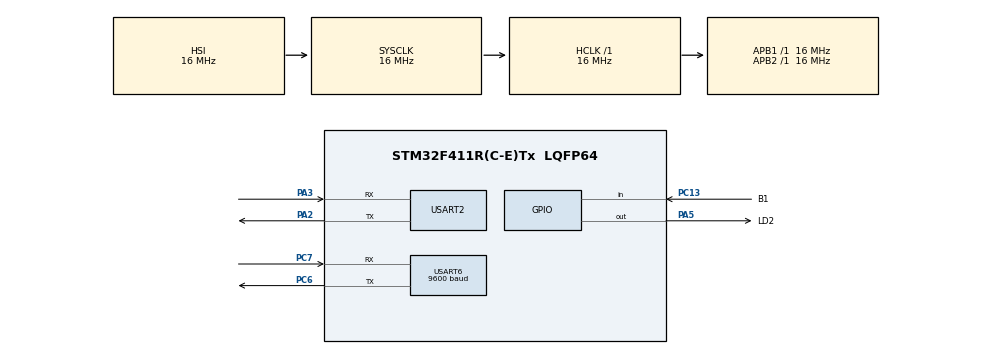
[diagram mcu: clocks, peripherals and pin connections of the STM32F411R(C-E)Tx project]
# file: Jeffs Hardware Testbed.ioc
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Dma.Request0=USART6_TX
Dma.USART6_TX.0.Direction=DMA_MEMORY_TO_PERIPH
Dma.USART6_TX.0.FIFOMode=DMA_FIFOMODE_DISABLE
Dma.USART6_TX.0.Instance=DMA2_Stream6
Dma.USART6_TX.0.MemDataAlignment=DMA_MDATAALIGN_BYTE
Dma.USART6_TX.0.MemInc=DMA_MINC_ENABLE
Dma.USART6_TX.0.Mode=DMA_NORMAL
Dma.USART6_TX.0.PeriphDataAlignment=DMA_PDATAALIGN_BYTE
Dma.USART6_TX.0.PeriphInc=DMA_PINC_DISABLE
Dma.USART6_TX.0.Priority=DMA_PRIORITY_LOW
FREERTOS.INCLUDE_vTaskDelayUntil=1
FREERTOS.Tasks01=myTask01,0,128,StartDefaultTask,Default,NULL,Static,myTask01Buffer,myTask01ControlBlock;myTask02,3,128,StartTask02,Default,NULL,Static,myTask02Buffer,myTask02ControlBlock
FREERTOS.configENABLE_FPU=1
Mcu.Family=STM32F4
Mcu.Name=STM32F411R(C-E)Tx
Mcu.Package=LQFP64
NVIC.DMA2_Stream6_IRQn=true\:5\:0\:false\:false\:true\:true\:false\:true
NVIC.PriorityGroup=NVIC_PRIORITYGROUP_4
NVIC.USART6_IRQn=true\:5\:0\:false\:false\:true\:true\:true\:true
PA2.Mode=Asynchronous
PA2.Signal=USART2_TX
PA3.Mode=Asynchronous
PA3.Signal=USART2_RX
PA5.GPIO_Label=LD2
PA5.Signal=GPIO_Output
PC13-ANTI_TAMP.GPIO_Label=B1
PC13-ANTI_TAMP.Signal=GPIO_Input
PC6.Mode=Asynchronous
PC6.Signal=USART6_TX
PC7.Mode=Asynchronous
PC7.Signal=USART6_RX
ProjectManager.HeapSize=0x200
ProjectManager.StackSize=0x400
ProjectManager.TargetToolchain=STM32CubeIDE
RCC.AHBFreq_Value=16000000
RCC.APB1Freq_Value=16000000
RCC.APB2Freq_Value=16000000
RCC.CortexFreq_Value=16000000
RCC.HSE_VALUE=25000000
RCC.HSI_VALUE=16000000
RCC.LSE_VALUE=32768
RCC.SYSCLKFreq_VALUE=16000000
RCC.VCOOutputFreq_Value=192000000
USART2.VirtualMode=VM_ASYNC
USART6.BaudRate=9600
USART6.VirtualMode=VM_ASYNC
VP_FREERTOS_VS_CMSIS_V1.Mode=CMSIS_V1
board=custom

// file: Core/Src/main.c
/* USER CODE BEGIN Header */
/**
  ******************************************************************************
  * @file           : main.c
  * @brief          : Main program body
  ******************************************************************************
  * @attention
  *
  * <h2><center>&copy; Copyright (c) 2021 STMicroelectronics.
  * All rights reserved.</center></h2>
  *
  * This software component is licensed by ST under Ultimate Liberty license
  * SLA0044, the "License"; You may not use this file except in compliance with
  * the License. You may obtain a copy of the License at:
  *                             www.st.com/SLA0044
  *
  ******************************************************************************
  */
/* USER CODE END Header */
#include "main.h"
#include "cmsis_os.h"

/* USER CODE BEGIN Includes */
#include "Nucleo_Profiles.h"
/* USER CODE END Includes */

UART_HandleTypeDef huart2;
UART_HandleTypeDef huart6;
DMA_HandleTypeDef hdma_usart6_tx;

osThreadId myTask01Handle;
uint32_t myTask01Buffer[ 128 ];
osStaticThreadDef_t myTask01ControlBlock;
osThreadId myTask02Handle;
uint32_t myTask02Buffer[ 128 ];
osStaticThreadDef_t myTask02ControlBlock;

void SystemClock_Config(void);
static void MX_GPIO_Init(void);
static void MX_DMA_Init(void);
static void MX_USART2_UART_Init(void);
static void MX_USART6_UART_Init(void);
void StartDefaultTask(void const * argument);
void StartTask02(void const * argument);

int main(void)
{

  /* MCU Configuration--------------------------------------------------------*/

  /* Reset of all peripherals, Initializes the Flash interface and the Systick. */
  HAL_Init();

  /* Configure the system clock */
  SystemClock_Config();

  /* Initialize all configured peripherals */
  MX_GPIO_Init();
  MX_DMA_Init();
  MX_USART2_UART_Init();
  MX_USART6_UART_Init();
  /* USER CODE BEGIN 2 */
  NucleoF4_Init();
  /* USER CODE END 2 */

  /* Create the thread(s) */
  /* definition and creation of myTask01 */
  osThreadStaticDef(myTask01, StartDefaultTask, osPriorityNormal, 0, 128, myTask01Buffer, &myTask01ControlBlock);
  myTask01Handle = osThreadCreate(osThread(myTask01), NULL);

  /* definition and creation of myTask02 */
  osThreadStaticDef(myTask02, StartTask02, osPriorityRealtime, 0, 128, myTask02Buffer, &myTask02ControlBlock);
  myTask02Handle = osThreadCreate(osThread(myTask02), NULL);

  /* Start scheduler */
  osKernelStart();

  /* We should never get here as control is now taken by the scheduler */
  /* Infinite loop */
  while (1)
  {

  }
}

void SystemClock_Config(void)
{
  RCC_OscInitTypeDef RCC_OscInitStruct = {0};
  RCC_ClkInitTypeDef RCC_ClkInitStruct = {0};

  /** Configure the main internal regulator output voltage
  */
  __HAL_RCC_PWR_CLK_ENABLE();
  __HAL_PWR_VOLTAGESCALING_CONFIG(PWR_REGULATOR_VOLTAGE_SCALE1);
  /** Initializes the RCC Oscillators according to the specified parameters
  * in the RCC_OscInitTypeDef structure.
  */
  RCC_OscInitStruct.OscillatorType = RCC_OSCILLATORTYPE_HSI;
  RCC_OscInitStruct.HSIState = RCC_HSI_ON;
  RCC_OscInitStruct.HSICalibrationValue = RCC_HSICALIBRATION_DEFAULT;
  RCC_OscInitStruct.PLL.PLLState = RCC_PLL_NONE;
  if (HAL_RCC_OscConfig(&RCC_OscInitStruct) != HAL_OK)
  {
    Error_Handler();
  }
  /** Initializes the CPU, AHB and APB buses clocks
  */
  RCC_ClkInitStruct.ClockType = RCC_CLOCKTYPE_HCLK|RCC_CLOCKTYPE_SYSCLK
                              |RCC_CLOCKTYPE_PCLK1|RCC_CLOCKTYPE_PCLK2;
  RCC_ClkInitStruct.SYSCLKSource = RCC_SYSCLKSOURCE_HSI;
  RCC_ClkInitStruct.AHBCLKDivider = RCC_SYSCLK_DIV1;
  RCC_ClkInitStruct.APB1CLKDivider = RCC_HCLK_DIV1;
  RCC_ClkInitStruct.APB2CLKDivider = RCC_HCLK_DIV1;

  if (HAL_RCC_ClockConfig(&RCC_ClkInitStruct, FLASH_LATENCY_0) != HAL_OK)
  {
    Error_Handler();
  }
}

static void MX_USART2_UART_Init(void)
{

  huart2.Instance = USART2;
  huart2.Init.BaudRate = 115200;
  huart2.Init.WordLength = UART_WORDLENGTH_8B;
  huart2.Init.StopBits = UART_STOPBITS_1;
  huart2.Init.Parity = UART_PARITY_NONE;
  huart2.Init.Mode = UART_MODE_TX_RX;
  huart2.Init.HwFlowCtl = UART_HWCONTROL_NONE;
  huart2.Init.OverSampling = UART_OVERSAMPLING_16;
  if (HAL_UART_Init(&huart2) != HAL_OK)
  {
    Error_Handler();
  }

}

static void MX_USART6_UART_Init(void)
{

  huart6.Instance = USART6;
  huart6.Init.BaudRate = 9600;
  huart6.Init.WordLength = UART_WORDLENGTH_8B;
  huart6.Init.StopBits = UART_STOPBITS_1;
  huart6.Init.Parity = UART_PARITY_NONE;
  huart6.Init.Mode = UART_MODE_TX_RX;
  huart6.Init.HwFlowCtl = UART_HWCONTROL_NONE;
  huart6.Init.OverSampling = UART_OVERSAMPLING_16;
  if (HAL_UART_Init(&huart6) != HAL_OK)
  {
    Error_Handler();
  }

}

static void MX_DMA_Init(void)
{

  /* DMA controller clock enable */
  __HAL_RCC_DMA2_CLK_ENABLE();

  /* DMA interrupt init */
  /* DMA2_Stream6_IRQn interrupt configuration */
  HAL_NVIC_SetPriority(DMA2_Stream6_IRQn, 5, 0);
  HAL_NVIC_EnableIRQ(DMA2_Stream6_IRQn);

}

static void MX_GPIO_Init(void)
{
  GPIO_InitTypeDef GPIO_InitStruct = {0};

  /* GPIO Ports Clock Enable */
  __HAL_RCC_GPIOC_CLK_ENABLE();
  __HAL_RCC_GPIOA_CLK_ENABLE();

  /*Configure GPIO pin Output Level */
  HAL_GPIO_WritePin(LD2_GPIO_Port, LD2_Pin, GPIO_PIN_RESET);

  /*Configure GPIO pin : B1_Pin */
  GPIO_InitStruct.Pin = B1_Pin;
  GPIO_InitStruct.Mode = GPIO_MODE_INPUT;
  GPIO_InitStruct.Pull = GPIO_NOPULL;
  HAL_GPIO_Init(B1_GPIO_Port, &GPIO_InitStruct);

  /*Configure GPIO pin : LD2_Pin */
  GPIO_InitStruct.Pin = LD2_Pin;
  GPIO_InitStruct.Mode = GPIO_MODE_OUTPUT_PP;
  GPIO_InitStruct.Pull = GPIO_NOPULL;
  GPIO_InitStruct.Speed = GPIO_SPEED_FREQ_LOW;
  HAL_GPIO_Init(LD2_GPIO_Port, &GPIO_InitStruct);

}

void StartDefaultTask(void const * argument)
{
  /* USER CODE BEGIN 5 */
  static TickType_t time_init = 0;

  /* Infinite loop */
  while(1) {

	  vTaskDelayUntil(&time_init, 100/portTICK_RATE_MS);
  }
  vTaskDelete(NULL);
  /* USER CODE END 5 */
}

void StartTask02(void const * argument)
{
  /* USER CODE BEGIN StartTask02 */
  /* Infinite loop */
  while(1) {
    break;
  }
  vTaskDelete(NULL);
  /* USER CODE END StartTask02 */
}

void Error_Handler(void)
{
  __disable_irq();
  while (1)
  {
  }
}

/************************ (C) COPYRIGHT STMicroelectronics *****END OF FILE****/
